# netx90_app register map
File version: 1.0
CPU: CM4 r0p1, little endian, MPU, FPU, 4 interrupt priority bits, 78 interrupts
Registers are 32-bit, read-write, reset 0x0 unless marked. A register's access mark holds for its fields unless they carry their own. Offsets are from the block's base; [hi:lo] are bit positions; {n}, {i} and the like mark numbered series.

## mmio_ctrl
Base 0xFF401300
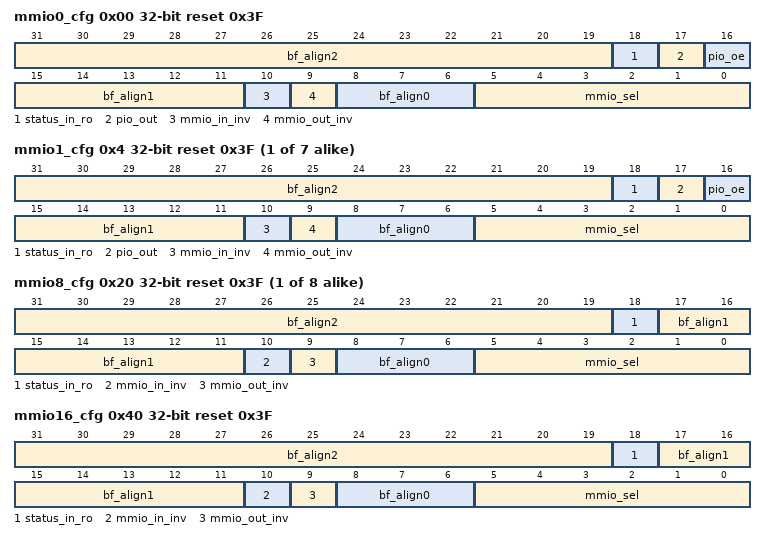
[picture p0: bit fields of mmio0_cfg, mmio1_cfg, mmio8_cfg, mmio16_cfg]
0x00 mmio0_cfg reset 0x3F (reset mask 0x7063F) — description too long, please enter short description.
  [31:19] bf_align2 — bitField alignment value for aeabi compatibility
  [18] status_in_ro — current input status of mmio0, could also be read from 'mmio_in_line_status' register
  [17] pio_out — PIO mode output drive level of mmio0, could also be programmd by 'mmio_pio_out_line_cfg' register (not protected) Changing this bit will also change according bit in 'mmio_pio_out_line_cfg register'.
  [16] pio_oe — PIO mode output enable of mmio0, could also be programmd by mmio_pio_oe_line_cfg register (not protected) Changing this bit will also change according bit in 'mmio_pio_oe_line_cfg register'.
  [15:11] bf_align1 — bitField alignment value for aeabi compatibility
  [10] mmio_in_inv — 1: invert input signal; 0: keep original signal polarity (access-key-protected)
  [9] mmio_out_inv — 1: invert output signal; 0: keep original signal polarity (access-key-protected)
  [8:6] bf_align0 — bitField alignment value for aeabi compatibility
  [5:0] mmio_sel — mmio0 signal selection (default: PIO mode, access-key-protected).
{0x0+4i} mmio{i}_cfg reset 0x3F (reset mask 0x7063F) (i=1..7) — Multiplexmatrix Configuration Register for MMIO{i} ------------------------------- Some bits of this register is protected by the netX access-key mechanism; changing this register is only possible by the following sequence: 1.: read out access-key from asic_ctrl_access_key register 2.: write back access-key to asic_ctrl_access_key register 3.: write desired value to this register ------------------------------- Core-inputs not mapped to any MMIO will be assigned to 0. If one core-connection is mapped to more than one MMIO, the core-input-state will be these ored MMIO-states. For signal selection codings (mmio*_sel) look at header of register adr_mmio0.
  [31:19] bf_align2 — bitField alignment value for aeabi compatibility
  [18] status_in_ro — current input status of mmio{i}, could also be read from 'mmio_in_line_status' register
  [17] pio_out — PIO mode output drive level of mmio{i}, could also be programmd by 'mmio_pio_out_line_cfg' register (not protected) Changing this bit will also change according bit in 'mmio_pio_out_line_cfg register'.
  [16] pio_oe — PIO mode output enable of mmio{i}, could also be programmd by mmio_pio_oe_line_cfg register (not protected) Changing this bit will also change according bit in 'mmio_pio_oe_line_cfg register'.
  [15:11] bf_align1 — bitField alignment value for aeabi compatibility
  [10] mmio_in_inv — 1: invert input signal; 0: keep original signal polarity (access-key-protected)
  [9] mmio_out_inv — 1: invert output signal; 0: keep original signal polarity (access-key-protected)
  [8:6] bf_align0 — bitField alignment value for aeabi compatibility
  [5:0] mmio_sel — mmio{i} signal selection (default: PIO mode, access-key-protected).
{0x0+4i} mmio{i}_cfg reset 0x3F (reset mask 0x4063F) (i=8..15) — Multiplexmatrix Configuration Register for MMIO{i} ------------------------------- Some bits of this register is protected by the netX access-key mechanism; changing this register is only possible by the following sequence: 1.: read out access-key from asic_ctrl_access_key register 2.: write back access-key to asic_ctrl_access_key register 3.: write desired value to this register ------------------------------- Core-inputs not mapped to any MMIO will be assigned to 0. If one core-connection is mapped to more than one MMIO, the core-input-state will be these ored MMIO-states. For signal selection codings (mmio*_sel) look at header of register adr_mmio0. Note: mmio{i} signal is a multiplex option of HIF_D{i} and has no PIO function.
  [31:19] bf_align2 — bitField alignment value for aeabi compatibility
  [18] status_in_ro — current input status of mmio{i} port HIF_D{i}. Could also be read from mmio_in_line_status register
  [17:11] bf_align1 — bitField alignment value for aeabi compatibility
  [10] mmio_in_inv — 1: invert input signal; 0: keep original signal polarity (access-key-protected)
  [9] mmio_out_inv — 1: invert output signal; 0: keep original signal polarity (access-key-protected)
  [8:6] bf_align0 — bitField alignment value for aeabi compatibility
  [5:0] mmio_sel — mmio{i} signal selection and multiplex function enable (access-key-protected). mmio{i} signal is a multiplex option of HIF_D{i} and will be selected when this bit-field is programmed to non-PIO MMIO function. PIO mode does not exist for this mmio{i} signal. Default value 0x3f deselects mmio{i} multiplex option.
0x40 mmio16_cfg reset 0x3F (reset mask 0x4063F) — Multiplexmatrix Configuration Register for MMIO16 ------------------------------- Some bits of this register is protected by the netX access-key mechanism; changing this register is only possible by the following sequence: 1.: read out access-key from asic_ctrl_access_key register 2.: write back access-key to asic_ctrl_access_key register 3.: write desired value to this register ------------------------------- Core-inputs not mapped to any MMIO will be assigned to 0. If one core-connection is mapped to more than one MMIO, the core-input-state will be these ored MMIO-states. For signal selection codings (mmio*_sel) look at header of register adr_mmio0. Note: mmio16 signal is a multiplex option of HIF_RDN and has no PIO function.
  [31:19] bf_align2 — bitField alignment value for aeabi compatibility
  [18] status_in_ro — current input status of mmio16 port HIF_RDN. Could also be read from mmio_in_line_status register
  [17:11] bf_align1 — bitField alignment value for aeabi compatibility
  [10] mmio_in_inv — 1: invert input signal; 0: keep original signal polarity (access-key-protected)
  [9] mmio_out_inv — 1: invert output signal; 0: keep original signal polarity (access-key-protected)
  [8:6] bf_align0 — bitField alignment value for aeabi compatibility
  [5:0] mmio_sel — mmio16 signal selection and multiplex function enable (access-key-protected). mmio16 signal is a multiplex option of HIF_RDN and will be selected when this bit-field is programmed to non-PIO MMIO function. PIO mode does not exist for this mmio16 signal. Default value 0x3f deselects mmio16 multiplex option.
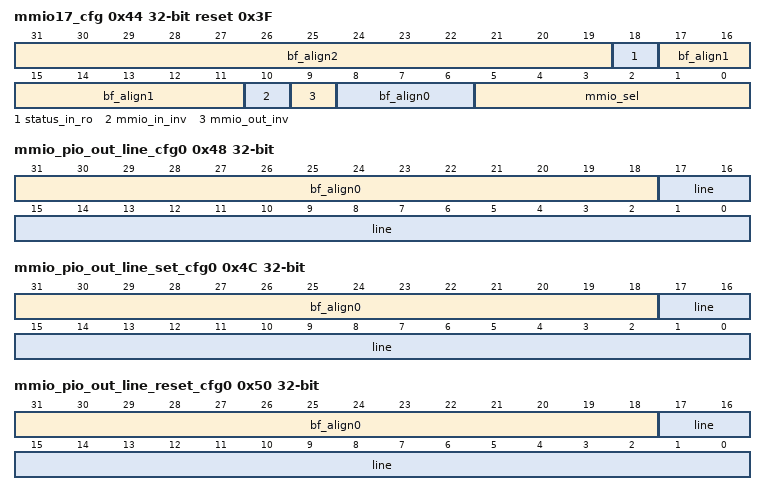
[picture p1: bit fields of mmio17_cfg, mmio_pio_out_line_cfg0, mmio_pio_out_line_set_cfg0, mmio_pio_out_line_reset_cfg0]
0x44 mmio17_cfg reset 0x3F (reset mask 0x4063F) — Multiplexmatrix Configuration Register for MMIO17 ------------------------------- Some bits of this register is protected by the netX access-key mechanism; changing this register is only possible by the following sequence: 1.: read out access-key from asic_ctrl_access_key register 2.: write back access-key to asic_ctrl_access_key register 3.: write desired value to this register ------------------------------- Core-inputs not mapped to any MMIO will be assigned to 0. If one core-connection is mapped to more than one MMIO, the core-input-state will be these ored MMIO-states. For signal selection codings (mmio*_sel) look at header of register adr_mmio0. Note: mmio17 signal is a multiplex option of HIF_DIRQ and has no PIO function.
  [31:19] bf_align2 — bitField alignment value for aeabi compatibility
  [18] status_in_ro — current input status of mmio17 port HIF_DIRQ. Could also be read from mmio_in_line_status register
  [17:11] bf_align1 — bitField alignment value for aeabi compatibility
  [10] mmio_in_inv — 1: invert input signal; 0: keep original signal polarity (access-key-protected)
  [9] mmio_out_inv — 1: invert output signal; 0: keep original signal polarity (access-key-protected)
  [8:6] bf_align0 — bitField alignment value for aeabi compatibility
  [5:0] mmio_sel — mmio17 signal selection and multiplex function enable (access-key-protected). mmio17 signal is a multiplex option of HIF_DIRQ and will be selected when this bit-field is programmed to non-PIO MMIO function. PIO mode does not exist for this mmio17 signal. Default value 0x3f deselects mmio17 multiplex option.
0x48 mmio_pio_out_line_cfg0 (reset mask 0x3FFFF) — MMIO PIO line output level register of MMIO 0 to 17. Changing bits here will change 'pio_out' bit of related mmio*_cfg register. Changes there will change related bit inside this register. Note: This register is not protected by netX access-key algorithm. Note MMIO8 has no PIO function. The value of bit 8 of (assotiated with MMIO8) will be ignored. MMIO9 has no PIO function. The value of bit 9 of (assotiated with MMIO9) will be ignored. MMIO10 has no PIO function. The value of bit 10 of (assotiated with MMIO10) will be ignored. MMIO11 has no PIO function. The value of bit 11 of (assotiated with MMIO11) will be ignored. MMIO12 has no PIO function. The value of bit 12 of (assotiated with MMIO12) will be ignored. MMIO13 has no PIO function. The value of bit 13 of (assotiated with MMIO13) will be ignored. MMIO14 has no PIO function. The value of bit 14 of (assotiated with MMIO14) will be ignored. MMIO15 has no PIO function. The value of bit 15 of (assotiated with MMIO15) will be ignored. MMIO16 has no PIO function. The value of bit 16 of (assotiated with MMIO16) will be ignored. MMIO17 has no PIO function. The value of bit 17 of (assotiated with MMIO17) will be ignored.
  [31:18] bf_align0 — bitField alignment value for aeabi compatibility
  [17:0] line — MMIO output state if related MMIO is in PIO mode. If related MMIO is not in PIO mode, programmed setting is ignored. Bit 0 controls MMIO0, bit 1 controls MMIO1, ... bit 17 controlls MMIO17.
0x4C mmio_pio_out_line_set_cfg0 (reset mask 0x3FFFF) — MMIO PIO line output level set register of MMIO 0 to 17. This register is for setting single MMIO PIOs to high level with a single access. In contrast to using the 'mmio_pio_out_line_cfg0' register no read-modify-write sequence (which could be interrupted) is required. Writing '1's here will activate the 'pio_out' bit of related 'mmio*_cfg' register and also activate the related bits in the 'mmio_pio_out_line_cfg0' register. For read this register returns the same value as the 'mmio_pio_out_line_cfg0' register. Note: This register is not protected by netX access-key algorithm. Note MMIO8 has no PIO function. The value of bit 8 of (assotiated with MMIO8) will be ignored. MMIO9 has no PIO function. The value of bit 9 of (assotiated with MMIO9) will be ignored. MMIO10 has no PIO function. The value of bit 10 of (assotiated with MMIO10) will be ignored. MMIO11 has no PIO function. The value of bit 11 of (assotiated with MMIO11) will be ignored. MMIO12 has no PIO function. The value of bit 12 of (assotiated with MMIO12) will be ignored. MMIO13 has no PIO function. The value of bit 13 of (assotiated with MMIO13) will be ignored. MMIO14 has no PIO function. The value of bit 14 of (assotiated with MMIO14) will be ignored. MMIO15 has no PIO function. The value of bit 15 of (assotiated with MMIO15) will be ignored. MMIO16 has no PIO function. The value of bit 16 of (assotiated with MMIO16) will be ignored. MMIO17 has no PIO function. The value of bit 17 of (assotiated with MMIO17) will be ignored.
  [31:18] bf_align0 — bitField alignment value for aeabi compatibility
  [17:0] line — Write '1's to set the related MMIO output to high level (when it is in PIO mode and output is enabled). If related MMIO is not in PIO mode, programmed setting is ignored. Bit 0 controls MMIO0, bit 1 controls MMIO1, ... bit 17 controlls MMIO17. For read the current value of the programmed output states is returned (i.e. the value of mmio_pio_out_line_cfg0).
0x50 mmio_pio_out_line_reset_cfg0 (reset mask 0x3FFFF) — MMIO PIO line output level reset register of MMIO 0 to 17. This register is for deactivating single MMIO PIOs with a single access. In contrast to using the 'mmio_pio_out_line_cfg0' register no read-modify-write sequence (which could be interrupted) is required. Writing '1's here will clear the 'pio_out' bit of related 'mmio*_cfg' register and also clear the related bits in the 'mmio_pio_out_line_cfg0' register. For read this register returns the same value as the 'mmio_pio_out_line_cfg0' register. Note: This register is not protected by netX access-key algorithm. Note MMIO8 has no PIO function. The value of bit 8 of (assotiated with MMIO8) will be ignored. MMIO9 has no PIO function. The value of bit 9 of (assotiated with MMIO9) will be ignored. MMIO10 has no PIO function. The value of bit 10 of (assotiated with MMIO10) will be ignored. MMIO11 has no PIO function. The value of bit 11 of (assotiated with MMIO11) will be ignored. MMIO12 has no PIO function. The value of bit 12 of (assotiated with MMIO12) will be ignored. MMIO13 has no PIO function. The value of bit 13 of (assotiated with MMIO13) will be ignored. MMIO14 has no PIO function. The value of bit 14 of (assotiated with MMIO14) will be ignored. MMIO15 has no PIO function. The value of bit 15 of (assotiated with MMIO15) will be ignored. MMIO16 has no PIO function. The value of bit 16 of (assotiated with MMIO16) will be ignored. MMIO17 has no PIO function. The value of bit 17 of (assotiated with MMIO17) will be ignored.
  [31:18] bf_align0 — bitField alignment value for aeabi compatibility
  [17:0] line — Write '1's to set the related MMIO output to low level (when it is in PIO mode and output is enabled). If related MMIO is not in PIO mode, programmed setting is ignored. Bit 0 controls MMIO0, bit 1 controls MMIO1, ... bit 17 controlls MMIO17. For read the current value of the programmed output states is returned (i.e. the value of mmio_pio_out_line_cfg0).
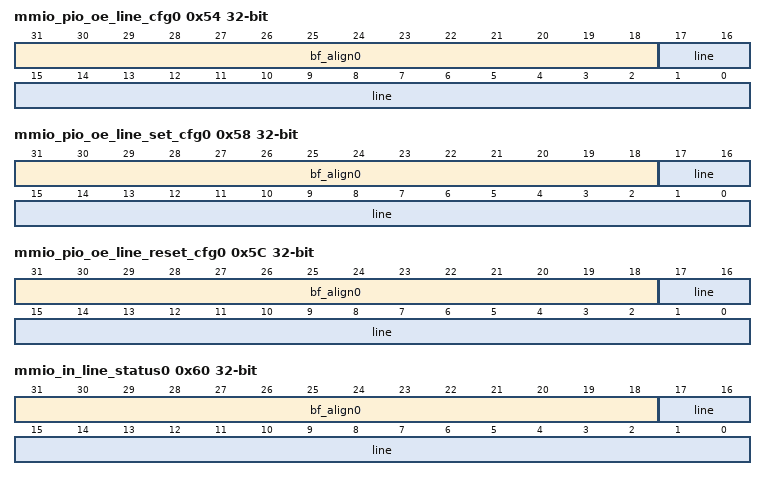
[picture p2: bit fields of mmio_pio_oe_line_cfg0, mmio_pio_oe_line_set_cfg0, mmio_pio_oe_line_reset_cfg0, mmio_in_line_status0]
0x54 mmio_pio_oe_line_cfg0 (reset mask 0x3FFFF) — MMIO PIO line output enable register of MMIO 0 to 17. Changing bits here will change 'pio_oe' bit of related mmio*_cfg register. Changes there will change related bit inside this register. Note: This register is not protected by netX access-key algorithm. Note MMIO8 has no PIO function. The value of bit 8 of (assotiated with MMIO8) will be ignored. MMIO9 has no PIO function. The value of bit 9 of (assotiated with MMIO9) will be ignored. MMIO10 has no PIO function. The value of bit 10 of (assotiated with MMIO10) will be ignored. MMIO11 has no PIO function. The value of bit 11 of (assotiated with MMIO11) will be ignored. MMIO12 has no PIO function. The value of bit 12 of (assotiated with MMIO12) will be ignored. MMIO13 has no PIO function. The value of bit 13 of (assotiated with MMIO13) will be ignored. MMIO14 has no PIO function. The value of bit 14 of (assotiated with MMIO14) will be ignored. MMIO15 has no PIO function. The value of bit 15 of (assotiated with MMIO15) will be ignored. MMIO16 has no PIO function. The value of bit 16 of (assotiated with MMIO16) will be ignored. MMIO17 has no PIO function. The value of bit 17 of (assotiated with MMIO17) will be ignored.
  [31:18] bf_align0 — bitField alignment value for aeabi compatibility
  [17:0] line — MMIO output enable if related MMIO is in PIO mode. If related MMIO is not in PIO mode, programmed setting is ignored. Bit 0 controls MMIO0, bit 1 controls MMIO1, ... bit 17 controlls MMIO17.
0x58 mmio_pio_oe_line_set_cfg0 (reset mask 0x3FFFF) — MMIO PIO line output enable set register of MMIO 0 to 17. This register is for activating single MMIO PIOs with a single access. In contrast to using the 'mmio_pio_oe_line_cfg0' register no read-modify-write sequence (which could be interrupted) is required. Writing '1's here will activate the 'pio_oe' bit of related 'mmio*_cfg' register and also activate the related bits in the 'mmio_pio_oe_line_cfg0' register. For read this register returns the same value as the 'mmio_pio_oe_line_cfg0' register. Note: This register is not protected by netX access-key algorithm. Note MMIO8 has no PIO function. The value of bit 8 of (assotiated with MMIO8) will be ignored. MMIO9 has no PIO function. The value of bit 9 of (assotiated with MMIO9) will be ignored. MMIO10 has no PIO function. The value of bit 10 of (assotiated with MMIO10) will be ignored. MMIO11 has no PIO function. The value of bit 11 of (assotiated with MMIO11) will be ignored. MMIO12 has no PIO function. The value of bit 12 of (assotiated with MMIO12) will be ignored. MMIO13 has no PIO function. The value of bit 13 of (assotiated with MMIO13) will be ignored. MMIO14 has no PIO function. The value of bit 14 of (assotiated with MMIO14) will be ignored. MMIO15 has no PIO function. The value of bit 15 of (assotiated with MMIO15) will be ignored. MMIO16 has no PIO function. The value of bit 16 of (assotiated with MMIO16) will be ignored. MMIO17 has no PIO function. The value of bit 17 of (assotiated with MMIO17) will be ignored.
  [31:18] bf_align0 — bitField alignment value for aeabi compatibility
  [17:0] line — Write '1's to activate the related MMIO output enable (when it is in PIO mode). If related MMIO is not in PIO mode, programmed setting is ignored. Bit 0 controls MMIO0, bit 1 controls MMIO1, ... bit 17 controlls MMIO17. For read the current value of the programmed output enables is returned (i.e. the value of mmio_pio_oe_line_cfg0).
0x5C mmio_pio_oe_line_reset_cfg0 (reset mask 0x3FFFF) — MMIO PIO line output enable reset register of MMIO 0 to 17. This register is for deactivating single MMIO PIOs with a single access. In contrast to using the 'mmio_pio_oe_line_cfg0' register no read-modify-write sequence (which could be interrupted) is required. Writing '1's here will clear the 'pio_oe' bit of related 'mmio*_cfg' register and also clear the related bits in the 'mmio_pio_oe_line_cfg0' register. For read this register returns the same value as the 'mmio_pio_oe_line_cfg0' register. Note: This register is not protected by netX access-key algorithm. Note MMIO8 has no PIO function. The value of bit 8 of (assotiated with MMIO8) will be ignored. MMIO9 has no PIO function. The value of bit 9 of (assotiated with MMIO9) will be ignored. MMIO10 has no PIO function. The value of bit 10 of (assotiated with MMIO10) will be ignored. MMIO11 has no PIO function. The value of bit 11 of (assotiated with MMIO11) will be ignored. MMIO12 has no PIO function. The value of bit 12 of (assotiated with MMIO12) will be ignored. MMIO13 has no PIO function. The value of bit 13 of (assotiated with MMIO13) will be ignored. MMIO14 has no PIO function. The value of bit 14 of (assotiated with MMIO14) will be ignored. MMIO15 has no PIO function. The value of bit 15 of (assotiated with MMIO15) will be ignored. MMIO16 has no PIO function. The value of bit 16 of (assotiated with MMIO16) will be ignored. MMIO17 has no PIO function. The value of bit 17 of (assotiated with MMIO17) will be ignored.
  [31:18] bf_align0 — bitField alignment value for aeabi compatibility
  [17:0] line — Write '1's to clear the related MMIO output enable (when it is in PIO mode). If related MMIO is not in PIO mode, programmed setting is ignored. Bit 0 controls MMIO0, bit 1 controls MMIO1, ... bit 17 controlls MMIO17. For read the current value of the programmed output enables is returned (i.e. the value of mmio_pio_oe_line_cfg0).
0x60 mmio_in_line_status0 ro (reset mask 0x3FFFF) — MMIO input line register of MMIO 0 to 17.
  [31:18] bf_align0 — bitField alignment value for aeabi compatibility
  [17:0] line — sampled MMIO input state. Does not depend whether MMIO is in PIO mode or not. Bit 0 monitors MMIO0, Bit 1 monitors MMIO1, ... bit 17 monitors MMIO17.
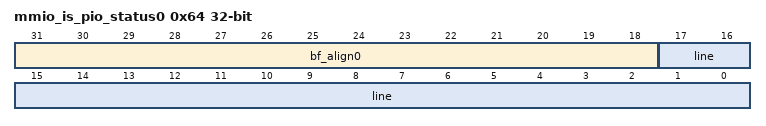
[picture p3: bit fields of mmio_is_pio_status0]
0x64 mmio_is_pio_status0 ro (reset mask 0x3FFFF) — MMIO mode line register of MMIO 0 to 17. Note: PIO Mode can be enabled or disabled in mmio_cfg registers. Note MMIO8 is not a standard-function MMIO and has no PIO function. When bit 8 is set, MMIO8-function will be active on HIF_D8. MMIO9 is not a standard-function MMIO and has no PIO function. When bit 9 is set, MMIO9-function will be active on HIF_D9. MMIO10 is not a standard-function MMIO and has no PIO function. When bit 10 is set, MMIO10-function will be active on HIF_D10. MMIO11 is not a standard-function MMIO and has no PIO function. When bit 11 is set, MMIO11-function will be active on HIF_D11. MMIO12 is not a standard-function MMIO and has no PIO function. When bit 12 is set, MMIO12-function will be active on HIF_D12. MMIO13 is not a standard-function MMIO and has no PIO function. When bit 13 is set, MMIO13-function will be active on HIF_D13. MMIO14 is not a standard-function MMIO and has no PIO function. When bit 14 is set, MMIO14-function will be active on HIF_D14. MMIO15 is not a standard-function MMIO and has no PIO function. When bit 15 is set, MMIO15-function will be active on HIF_D15. MMIO16 is not a standard-function MMIO and has no PIO function. When bit 16 is set, MMIO16-function will be active on HIF_RDN. MMIO17 is not a standard-function MMIO and has no PIO function. When bit 17 is set, MMIO17-function will be active on HIF_DIRQ.
  [31:18] bf_align0 — bitField alignment value for aeabi compatibility
  [17:0] line — Bit 0 shows status of MMIO0, Bit 1 shows status of MMIO1, ... bit 17 shows MMIO17. If the MMIO is the standard function of the netX IO (i.e. the netX pin name is MMIOx), the bit of the related MMIO shows whether the MMIO is in PIO mode or not. If the MMIO is a multiplex function of a netX IO (i.e. the netX pin name is another than MMIOx), a PIO function is not available by the MMIO function. In this case the bit of the related MMIO shows whether the MMIO function is selected or not. { | | The related MMIO is a standard- Value Status function MMIO (netX MMIOx pin) yes 0 The related MMIO is not in PIO mode (is assigned to core functionality). yes 1 The related MMIO is in PIO mode (is not assigned to core functionality). no 0 The MMIO-function of the netX IO is selected and assigned to a MMIO core functionality. no 1 The MMIO-function of the related netX IO is not selected. } Note: When the MMIO function is selected it could be possible that also another IO multiplex function is activated (e.g. by global IO-configuration registers 'io_config'). This function could have higher priority in global IO multiplexing and could deselect the MMIO function.
